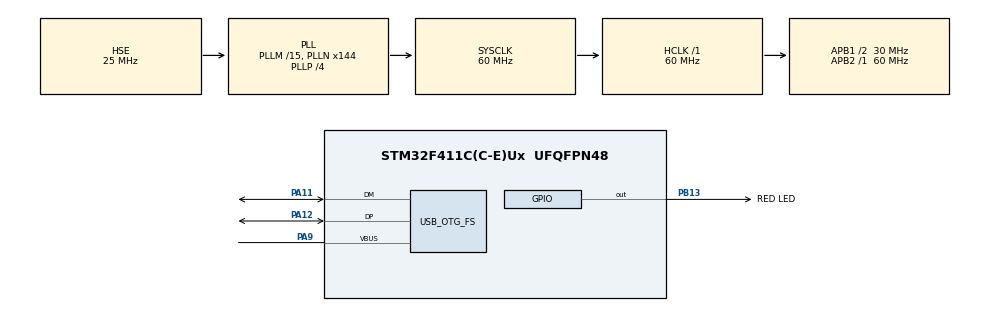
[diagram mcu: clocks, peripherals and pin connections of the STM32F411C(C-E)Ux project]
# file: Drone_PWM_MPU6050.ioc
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Mcu.Family=STM32F4
Mcu.Name=STM32F411C(C-E)Ux
Mcu.Package=UFQFPN48
NVIC.OTG_FS_IRQn=true\:0\:0\:false\:false\:true\:false\:true\:true
NVIC.PriorityGroup=NVIC_PRIORITYGROUP_4
PA11.Mode=Device_Only
PA11.Signal=USB_OTG_FS_DM
PA12.Mode=Device_Only
PA12.Signal=USB_OTG_FS_DP
PA13.Mode=Trace_Asynchronous_SW
PA13.Signal=SYS_JTMS-SWDIO
PA14.Mode=Trace_Asynchronous_SW
PA14.Signal=SYS_JTCK-SWCLK
PA9.Mode=Activate_VBUS
PA9.Signal=USB_OTG_FS_VBUS
PB13.GPIO_Label=RED LED
PB13.Signal=GPIO_Output
PB3.Mode=Trace_Asynchronous_SW
PB3.Signal=SYS_JTDO-SWO
PH0\ -\ OSC_IN.Mode=HSE-External-Oscillator
PH0\ -\ OSC_IN.Signal=RCC_OSC_IN
PH1\ -\ OSC_OUT.Mode=HSE-External-Oscillator
PH1\ -\ OSC_OUT.Signal=RCC_OSC_OUT
ProjectManager.HeapSize=0x200
ProjectManager.StackSize=0x400
ProjectManager.TargetToolchain=STM32CubeIDE
RCC.48MHZClocksFreq_Value=48000000
RCC.AHBFreq_Value=60000000
RCC.APB1CLKDivider=RCC_HCLK_DIV2
RCC.APB1Freq_Value=30000000
RCC.APB1TimFreq_Value=60000000
RCC.APB2Freq_Value=60000000
RCC.APB2TimFreq_Value=60000000
RCC.CortexFreq_Value=60000000
RCC.HCLKFreq_Value=60000000
RCC.HSE_VALUE=25000000
RCC.HSI_VALUE=16000000
RCC.LSE_VALUE=32768
RCC.PLLM=15
RCC.PLLN=144
RCC.PLLP=RCC_PLLP_DIV4
RCC.PLLQ=5
RCC.SYSCLKFreq_VALUE=60000000
RCC.SYSCLKSource=RCC_SYSCLKSOURCE_PLLCLK
RCC.VCOOutputFreq_Value=240000000
USB_DEVICE.CLASS_NAME_FS=CDC
USB_DEVICE.VirtualMode=Cdc
USB_DEVICE.VirtualModeFS=Cdc_FS
USB_OTG_FS.VirtualMode=Device_Only
VP_USB_DEVICE_VS_USB_DEVICE_CDC_FS.Mode=CDC_FS
board=custom

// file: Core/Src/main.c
/* USER CODE BEGIN Header */
/**
  ******************************************************************************
  * @file           : main.c
  * @brief          : Main program body
  ******************************************************************************
  * @attention
  *
  * Copyright (c) 2025 STMicroelectronics.
  * All rights reserved.
  *
  * This software is licensed under terms that can be found in the LICENSE file
  * in the root directory of this software component.
  * If no LICENSE file comes with this software, it is provided AS-IS.
  *
  ******************************************************************************
  */
/* USER CODE END Header */
#include "main.h"
#include "usbd_cdc_if.h"
#include "usb_device.h"
#include "gpio.h"

/* USER CODE BEGIN Includes */
#include <stdio.h>
/* USER CODE END Includes */

void SystemClock_Config(void);
/* USER CODE BEGIN PFP */
// 0. Prototype RX Handler so usbd_cdc_if.c can call on it */
void MyRxHandler(uint8_t * data, uint32_t len);

/* USER CODE END PFP */

int main(void)
{

  /* MCU Configuration--------------------------------------------------------*/

  /* Reset of all peripherals, Initializes the Flash interface and the Systick. */
  HAL_Init();

  /* Configure the system clock */
  SystemClock_Config();

  /* Initialize all configured peripherals */
  MX_GPIO_Init();
  MX_USB_DEVICE_Init(); // this brings up the CDC interface

  /* USER CODE BEGIN 2 */
  // greeting right after USB comes up
  {
	  uint8_t msg[] = "Hello MPU6050!\r\n";
	  if (CDC_Transmit_FS(msg, sizeof(msg)-1) != USBD_OK) {
	  }
  }
  /* USER CODE END 2 */

  /* Infinite loop */
  while (1)
  {

    /* USER CODE BEGIN 3 */
	HAL_GPIO_TogglePin(RED_LED_GPIO_Port, RED_LED_Pin);
	HAL_Delay(500); // delay 500 ms
  /* USER CODE END 3 */
}
}

/* 2. Definition of receive handler*/
void MyRxHandler(uint8_t * data, uint32_t len)
{
	CDC_Transmit_FS(data, len);
}

void SystemClock_Config(void)
{
  RCC_OscInitTypeDef RCC_OscInitStruct = {0};
  RCC_ClkInitTypeDef RCC_ClkInitStruct = {0};

  /** Configure the main internal regulator output voltage
  */
  __HAL_RCC_PWR_CLK_ENABLE();
  __HAL_PWR_VOLTAGESCALING_CONFIG(PWR_REGULATOR_VOLTAGE_SCALE1);

  /** Initializes the RCC Oscillators according to the specified parameters
  * in the RCC_OscInitTypeDef structure.
  */
  RCC_OscInitStruct.OscillatorType = RCC_OSCILLATORTYPE_HSE;
  RCC_OscInitStruct.HSEState = RCC_HSE_ON;
  RCC_OscInitStruct.PLL.PLLState = RCC_PLL_ON;
  RCC_OscInitStruct.PLL.PLLSource = RCC_PLLSOURCE_HSE;
  RCC_OscInitStruct.PLL.PLLM = 15;
  RCC_OscInitStruct.PLL.PLLN = 144;
  RCC_OscInitStruct.PLL.PLLP = RCC_PLLP_DIV4;
  RCC_OscInitStruct.PLL.PLLQ = 5;
  if (HAL_RCC_OscConfig(&RCC_OscInitStruct) != HAL_OK)
  {
    Error_Handler();
  }

  /** Initializes the CPU, AHB and APB buses clocks
  */
  RCC_ClkInitStruct.ClockType = RCC_CLOCKTYPE_HCLK|RCC_CLOCKTYPE_SYSCLK
                              |RCC_CLOCKTYPE_PCLK1|RCC_CLOCKTYPE_PCLK2;
  RCC_ClkInitStruct.SYSCLKSource = RCC_SYSCLKSOURCE_PLLCLK;
  RCC_ClkInitStruct.AHBCLKDivider = RCC_SYSCLK_DIV1;
  RCC_ClkInitStruct.APB1CLKDivider = RCC_HCLK_DIV2;
  RCC_ClkInitStruct.APB2CLKDivider = RCC_HCLK_DIV1;

  if (HAL_RCC_ClockConfig(&RCC_ClkInitStruct, FLASH_LATENCY_1) != HAL_OK)
  {
    Error_Handler();
  }
}

void Error_Handler(void)
{
  __disable_irq();
  while (1)
  {
  }
}
